# MB9BF32xL register map
File version: 1.7
Registers are 8-bit, read-write, reset 0x0 unless marked. A register's access mark holds for its fields unless they carry their own. Offsets are from the block's base; lines under a group give offsets from that group; [hi:lo] are bit positions; {n}, {i} and the like mark numbered series; 'fields as' and 'values as' point back to an identical list; <NAME> marks a mode.

## Memory map
0x40000000 FLASH_IF blocks up to offset 0x104 — Flash Memory
0x40010000 CRG blocks up to offset 0x69 — Clock Unit Registers
0x40011000 HWWDT blocks up to offset 0xC04 — Hardware Watchdog Timer
0x40012000 SWWDT blocks up to offset 0xC04 — Software Watchdog Timer
0x40015000 DTIM blocks up to offset 0x3C — Dual Timer
0x40020000 MFT0 blocks up to offset 0xC2 — Multifunction Timer 0
0x40024000 MFT_PPG blocks up to offset 0x381 — PPG Configuration
0x40025000 BT0 blocks up to offset 0x12 — Base Timer 0
0x40025040 BT1 blocks up to offset 0x12
0x40025080 BT2 blocks up to offset 0x12
0x400250C0 BT3 blocks up to offset 0x12
0x40025100 BTIOSEL03 size 0x2 — Base Timer I/O Select
0x40025200 BT4 blocks up to offset 0x12
0x40025240 BT5 blocks up to offset 0x12
0x40025280 BT6 blocks up to offset 0x12
0x400252C0 BT7 blocks up to offset 0x12
0x40025300 BTIOSEL47 blocks up to offset 0x2 — Base Timer I/O Select
0x40025F00 SBSSR blocks up to offset 0xFE — Software-based Simultaneous Startup Register
0x40026000 QPRC0 blocks up to offset 0x40 — Quadrature Position/Revolution Counter 0
0x40026040 QPRC1 blocks up to offset 0x40
0x40027000 ADC0 blocks up to offset 0x3E — ADC0 Registers
0x40027100 ADC1 blocks up to offset 0x3E
0x4002E000 CRTRIM blocks up to offset 0x10 — CR Trimming Registers
0x40030000 EXTI blocks up to offset 0x19 — External Interrupt and NMI Control
0x40031000 INTREQ blocks up to offset 0x218 — Interrupts
0x40033000 GPIO size 0x740 — General-purpose I/O ports
0x40035000 LVD blocks up to offset 0x11 — Low-voltage Detection
0x40035100 DS blocks up to offset 0x816 — Low Power Consumption Mode
0x40036000 USBCLK blocks up to offset 0x31 — USB Clock
0x40038000 MFS0 blocks up to offset 0x1E — Multi-function Serial Interface 0
0x40038100 MFS1 blocks up to offset 0x1E
0x40038200 MFS2 blocks up to offset 0x1E
0x40038300 MFS3 blocks up to offset 0x1E
0x40038400 MFS4 blocks up to offset 0x1E
0x40038500 MFS5 blocks up to offset 0x1E
0x40038600 MFS6 blocks up to offset 0x1E
0x40038700 MFS7 blocks up to offset 0x1E
0x40039000 CRC blocks up to offset 0x10 — CRC Registers
0x4003A000 WC blocks up to offset 0x15 — Watch Counter
0x4003B000 RTC blocks up to offset 0x31 — REAL-TIME CLOCK
0x40040000 USB0 blocks up to offset 0x2176 — USB0 Function
0x40060000 DMAC blocks up to offset 0x90 — DMAC Registers

## Interrupts
0 CSV (CRG)
1 SWDT (SWWDT)
2 LVD
3 WFG (MFT0)
4 EXTINT0_7 (EXTI)
5 EXTINT8_23 (EXTI)
6 DTIM_QDU (DTIM)
{2n+7} MFS{n}RX (MFS{n}) (n=0..7)
{2n+8} MFS{n}TX (MFS{n}) (n=0..7)
23 PPG (MFT_PPG)
24 OSC_PLL_WC_RTC (CRG)
25 ADC0
26 ADC1
28 FRTIM (MFT0)
29 INCAP (MFT0)
30 OUTCOMP (MFT0)
31 BTIM0_7 (BT0)
34 USB0F (USB0)
35 USB0F_USB0H (USB0)
{n+38} DMAC{n} (DMAC) (n=0..7)

## FLASH_IF — Flash Memory
Base 0x40000000
0x04 FRWTR 32-bit — Flash Read Wait Register
  [1:0] RWT — Read Wait Cycle
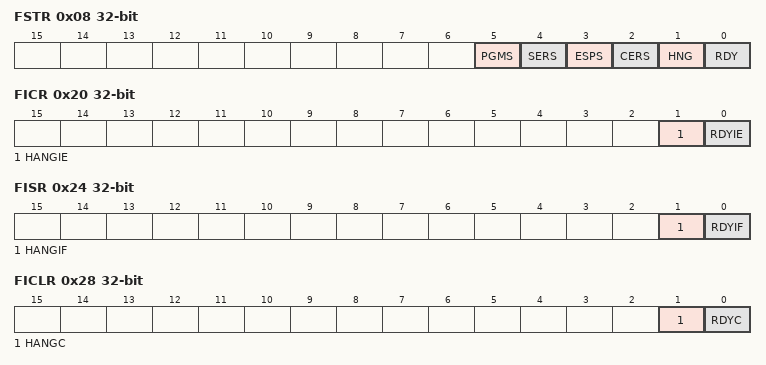
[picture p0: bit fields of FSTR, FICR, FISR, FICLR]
0x08 FSTR 32-bit ro — Flash Status Register
  [5] PGMS — Flash Program Status
  [4] SERS — Flash Sector Erase Status
  [3] ESPS — Flash Erase Suspend Status
  [2] CERS — Flash Chip Erase Status
  [1] HNG — Flash Hang flag
  [0] RDY — Flash Rdy
0x20 FICR 32-bit — Flash Interrupt Control Register
  [1] HANGIE — HANG Interrupt Enable
  [0] RDYIE — RDY Interrupt Enable
0x24 FISR 32-bit — Flash Interrupt Status Register
  [1] HANGIF — HANG Interrupt Flag
  [0] RDYIF — RDY Interrupt Flag
0x28 FICLR 32-bit wo — Flash Interrupt Clear Register
  [1] HANGC rw — HANG Interrupt Clear
  [0] RDYC rw — RDY Interrupt Clear
0x100 CRTRMM 32-bit ro reset not defined — CR Trimming Data Mirror Register
  [9:0] TRMM — CR Trimming Data Mirror

## CRTRIM — CR Trimming Registers
Base 0x4002E000
0x00 MCR_PSR reset 0x1 — High-speed CR oscillation Frequency Division Setup Register
  [1:0] CSR — High-speed CR oscillation frequency division ratio setting bits
0x04 MCR_FTRM 16-bit reset 0x180 — High-speed CR oscillation Frequency Trimming Register
  [9:0] TRD — Frequency trimming setup bits
0x0C MCR_RLR 32-bit reset 0x1 — High-Speed CR Oscillation Register Write-Protect Register
  [31:0] TRMLCK — Register write-protect bits

## Notices in the file
Licence Terms
FUJITSU SEMICONDUCTOR LIMITED (gLICENSORh) hereby grants and
you (gLICENSEEh) hereby accept a non transferable, non-exclusive
licence to use and copy the deliverables (gDeliverablesh) solely for
the purpose of; (i) developing LICENSEEfs development tools and
distributing such development tools to third parties; (ii) generating
derivative representations of the Deliverables to develop and debug
software for LICENSORfs targeted devices or device series identified
within the Deliverables, (together the gPurposeh) under the following
terms and conditions:
1. Ownership.
The Deliverables are the property of LICENSOR. LICENSEE acquires no
right, title or interest in the Deliverables other than the licence
rights granted herein.
2. Use.
LICENSEE shall only be permitted to use the Deliverables for the
Purpose. LICENSEE shall not reverse engineer, decompile or
disassemble the Deliverables, in whole or in part.
3. Copies.
All copies of the Deliverables must bear the same notice(s) contained
on the original copies of the Deliverables.
4. No Warranty.
THE DELIVERABLES ARE PROVIDED gAS ISh AND ANY EXPRESS, IMPLIED OR
STATUTORY WARRANTIES, INCLUDING, BUT NOT LIMITED TO, THE IMPLIED
WARRANTIES OF MERCHANTABILITY, SATISFACTORY QUALITY AND FITNESS FOR
A PARTICULAR PURPOSE ARE DISCLAIMED.
IN NO EVENT SHALL LICENSOR BE LIABLE FOR ANY DIRECT, INDIRECT,
INCIDENTAL, SPECIAL, EXEMPLARY, OR CONSEQUENTIAL DAMAGES HOWEVER CAUSED
AND ON ANY THEORY OF LIABILITY, WHETHER IN CONTRACT, STRICT LIABILITY,
OR TORT (INCLUDING NEGLIGENCE OR OTHERWISE) ARISING IN ANY WAY OUT OF
THE USE OF THE DELIVERABLES, EVEN IF ADVISED OF THE POSSIBILITY OF SUCH
DAMAGE.
LICENSEE EXPRESSLY ASSUMES ALL LIABILITIES AND RISKS, FOR USE OR
OPERATION OF THE DELIVERABLES.
5.In the event that LICENSEE receives early access to the Deliverables,
LICENSEE acknowledges and agrees that;
(a) notwithstanding the licence grants above, LICENSEE shall only be
permitted to use the Deliverables solely internally for evaluation and
providing feedback to LICENSOR;
(b) except with respect to the limited licence grants in 5(a), LICENSEE
shall be subject to all of the terms and conditions set out above; and
(c) the Deliverables are confidential information and LICENSEE shall
maintain in confidence the Deliverables and apply security measures no
less stringent than the measures that LICENSEE applies to its own like
information, but not less than a reasonable degree of care, to prevent
unauthorised disclosure and use of the Deliverables.
